# MKL28T7_CORE1 register map
Vendor: Freescale Semiconductor, Inc.; Series: Kinetis_L; File version: 1.6
CPU: CM0PLUS r0p0, little endian, no MPU, no FPU, VTOR, 2 interrupt priority bits
Registers are 32-bit, read-write, reset 0x0 unless marked. A register's access mark holds for its fields unless they carry their own. Offsets are from the block's base; [hi:lo] are bit positions; {n}, {i} and the like mark numbered series; 'fields as' and 'values as' point back to an identical list.

## XRDC
Base 0x40014000; register names take the prefix XRDC_
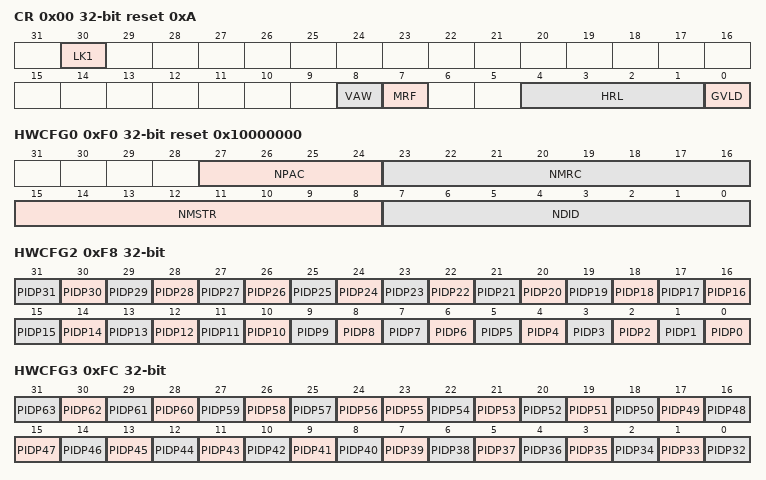
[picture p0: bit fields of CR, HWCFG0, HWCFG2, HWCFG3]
0x00 CR reset 0xA — Control Register
  [30] LK1 — 1-bit Lock
    0=Register can be written by any secure privileged write; 1=Register is locked (read-only) until the next reset
  [8] VAW ro — Virtualization aware
    0=Implementation is not virtualization aware; 1=Implementation is virtualization aware
  [7] MRF ro — Memory Region Format
    0=Kinetis format based on ARM Cortex-M processor core definition
  [4:1] HRL ro — Hardware Revision Level
  [0] GVLD — Global Valid (XRDC global enable/disable).
    0=XRDC is disabled. All accesses from all bus masters to all slaves are allowed.; 1=XRDC is enabled
0xF0 HWCFG0 ro reset 0x10000000 — Hardware Configuration Register 0
  [27:24] NPAC — Number of PACs
  [23:16] NMRC — Number of MRCs
  [15:8] NMSTR — Number of bus masters
  [7:0] NDID — Number of domains
0xF4 HWCFG1 ro — Hardware Configuration Register 1
  [3:0] DID — Domain identifier number
0xF8 HWCFG2 ro reset not defined — Hardware Configuration Register 2
  [n] PIDP{n} (n=0..31) — Process identifier present from bus master {n}
    0=Bus master {n} does not source a process identifier register. The XRDC_MDAC logic provides the needed PID for processor cores.; 1=Bus master {n} sources a process identifier register to the XRDC_MDAC logic
0xFC HWCFG3 ro reset not defined — Hardware Configuration Register 3
  [n-32] PIDP{n} (n=56..63) — Process identifier present from bus master {n}
    values as HWCFG2.PIDP0
  [23] PIDP55 — Process identifier present from bus master 55
    0=Bus master 55 does not source a process identifier register. The XRDC_MDAC logic provides the needed PID for processor cores.; 1=Bus master 55sources a process identifier register to the XRDC_MDAC logic
  [n-32] PIDP{n} (n=32..54) — Process identifier present from bus master {n}
    values as HWCFG2.PIDP0
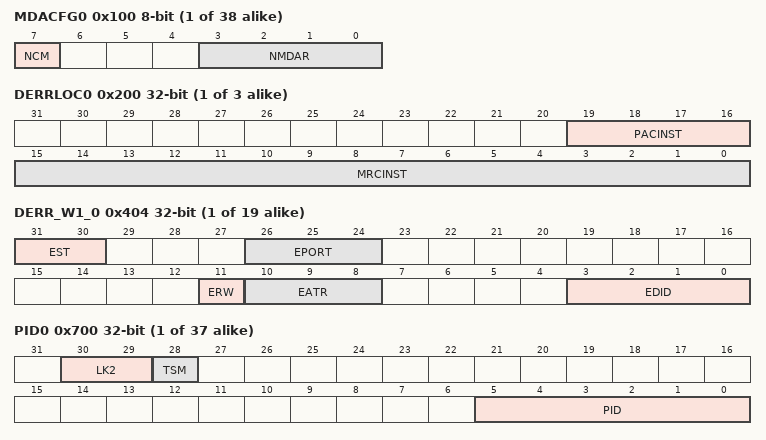
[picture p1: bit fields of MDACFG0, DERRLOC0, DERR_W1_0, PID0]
{0x100+i} MDACFG{i} (i=0..37) 8-bit ro — Master Domain Assignment Configuration Register
  [7] NCM — Non-CPU Master
    0=Bus master is a processor; 1=Bus master is a non-processor
  [3:0] NMDAR — Number of master domain assignment registers for bus master n
{0x140+i} MRCFG{i} (i=0..1) 8-bit ro — Memory Region Configuration Register
  [4:0] NMGD — Number of memory region descriptors for MRC i
{0x200+4i} DERRLOC{i} (i=0..2) ro — Domain Error Location Register
  [19:16] PACINST — PAC instance
    0=The PAC has not detected an access violation or is not physically present; 1=The PAC has detected one or more access violations for this domain
  [15:0] MRCINST — MRC instance
    0=The MRC has not detected an access violation or is not physically present; 1=The MRC has detected one or more access violations for this domain
{0x400+0x10*i} DERR_W0_{i} (i=0..18) ro — Domain Error Word0 Register
  [31:0] EADDR — Error address. This is the access address that generated an access violation.
{0x404+0x10*i} DERR_W1_{i} (i=0..18) ro — Domain Error Word1 Register
  [31:30] EST — Error state
    0=No access violation has been detected; 1=No access violation has been detected; 2=A single access violation has been detected; 3=Multiple access violations for this domain have been detected by this submodule instance. Only the address and attribute information for the first error have been captured in DERR_W0_n and DERR_W1_n.
  [26:24] EPORT — Error port
  [11] ERW — Error read/write
    0=Read access; 1=Write access
  [10:8] EATR — Error attributes. This field captures certain attributes of the access violation.
    0=Secure user mode, instruction fetch access; 1=Secure user mode, data access; 2=Secure privileged mode, instruction fetch access; 3=Secure privileged mode, data access; 4=Nonsecure user mode, instruction fetch access; 5=Nonsecure user mode, data access; 6=Nonsecure privileged mode, instruction fetch access; 7=Nonsecure privileged mode, data access
  [3:0] EDID — Error domain identifier. This field captures the domain identifier of the access violation.
{0x408+0x10*i} DERR_W2_{i} (i=0..18) ro — Domain Error Word2 Register
{0x40C+0x10*i} DERR_W3_{i} (i=0..18) — Domain Error Word3 Register
  [31:30] RECR wo — Rearm Error Capture Registers
{0x700+4i} PID{i} (i=0..36) — Process Identifier
  [30:29] LK2 — Lock
    0=Register can be written by any secure privileged write; 1=Register can be written by any secure privileged write; 2=Register can only be written by a secure privileged write from bus master n; 3=Register is locked (read-only) until the next reset
  [28] TSM — Three-state model
  [5:0] PID — Process identifier
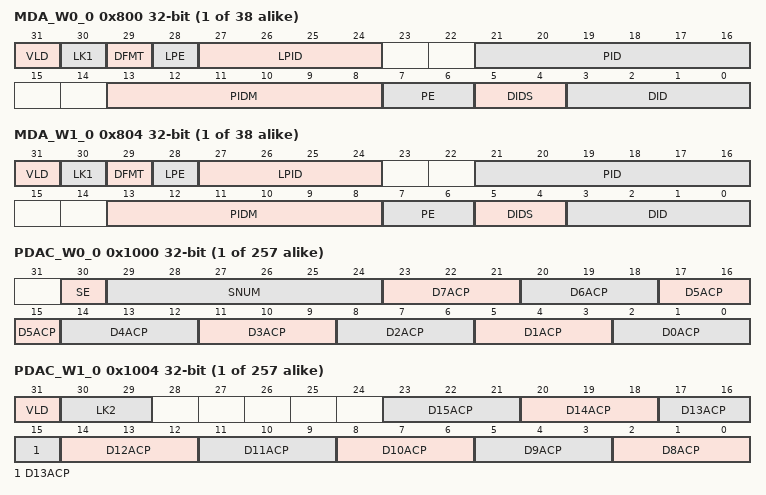
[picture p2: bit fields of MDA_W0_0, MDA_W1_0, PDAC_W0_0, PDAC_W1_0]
{0x800+0x20*i} MDA_W0_{i} (i=0..37) — Master Domain Assignment Wm,n (DFMT=0)
  [31] VLD — Valid
    0=The Wm domain assignment is invalid; 1=The Wm domain assignment is valid
  [30] LK1 — 1-bit Lock
    values as CR.LK1
  [29] DFMT ro — Domain format
  [28] LPE — Logical partition enable
  [27:24] LPID — Logical partition Identifier
  [21:16] PID — Process Identifier
  [13:8] PIDM — Process Identifier Mask
  [7:6] PE — Process identifier enable
    0=No process identifier is included in the domain hit evaluation; 1=No process identifier is included in the domain hit evaluation; 2=The process identifier is included in the domain hit evaluation as defined by the expression: partial_domain_hit = (PE == 2) && ((PID & ~PIDM) == (XRDC_PIDn[PID] & ~PIDM)); 3=The process identifier is included in the domain hit evaluation as defined by the expression: partial_domain_hit = (PE == 3) && ((PID & ~PIDM) == (XRDC_PIDn[PID] & ~PIDM))
  [5:4] DIDS — DID Select
    0=Use MDAn[3:0] as the domain identifier; 1=Use the input DID as the domain identifier; 2=Use MDAn[3:2] concatenated with the low-order 2 bits of the input DID (DID_in[1:0]) as the domain identifier
  [3:0] DID — Domain identifier
{0x804+0x20*i} MDA_W1_{i} (i=0..37) — Master Domain Assignment Wm,n (DFMT=0)
  fields as MDA_W0_0
{0x1000+8i} PDAC_W0_{i} (i=0..256) — Peripheral Domain Access Control W0
  [30] SE — Semaphore enable
    0=Do not include a semaphore in the DxACP evaluation; 1=Include the semaphore defined by W0[SNUM] in the DxACP evaluation
  [29:24] SNUM — Semaphore number. Include this hardware semaphore in the DxACP access evaluation.
  [23:21] D7ACP — Domain 7 access control policy
  [3n+2:3n] D{n}ACP (n=0..6) — Domain {n} access control policy. See description for D7ACP .
{0x1004+8i} PDAC_W1_{i} (i=0..256) — Peripheral Domain Access Control W1
  [31] VLD — Valid
    0=The PDACn assignment is invalid; 1=The PDACn assignment is valid
  [30:29] LK2 — Lock
    0=Entire PDACn can be written; 1=Entire PDACn can be written; 2=Domain "x" can only update the DxACP field; no other PDACn fields can be written; 3=PDACn is locked (read-only) until the next reset
  [3n-22:3n-24] D{n}ACP (n=8..15) — Domain {n} access control policy. See description for D7ACP .
{0x2000+0x20*i} MRGD_W0_{i} (i=0..23) — Memory Region Descriptor W0
  [31:5] BASEADDR — Base Address
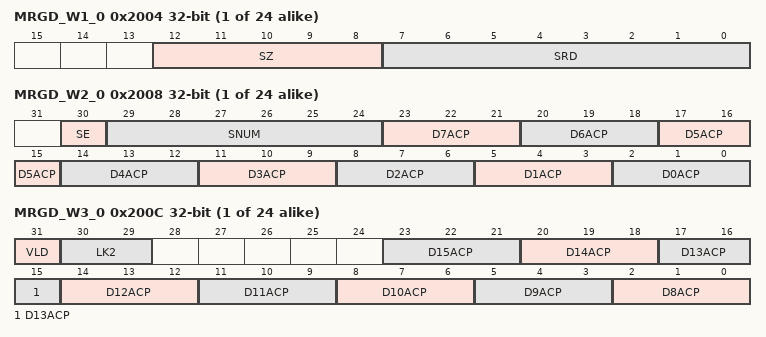
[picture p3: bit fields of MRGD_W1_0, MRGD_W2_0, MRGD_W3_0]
{0x2004+0x20*i} MRGD_W1_{i} (i=0..23) — Memory Region Descriptor W1
  [12:8] SZ — Region size
  [7:0] SRD — Subregion disable
{0x2008+0x20*i} MRGD_W2_{i} (i=0..23) — Memory Region Descriptor W2
  [30] SE — Semaphore enable
    0=Do not include a semaphore in the DxACP evaluation; 1=Include the semaphore defined by W2[SNUM] in the DxACP evaluation
  [29:24] SNUM — Semaphore number. Include this hardware semaphore in the DxACP access evaluation.
  [23:21] D7ACP — Domain 7 access control policy
  [3n+2:3n] D{n}ACP (n=0..6) — Domain {n} access control policy. See description for D7ACP .
{0x200C+0x20*i} MRGD_W3_{i} (i=0..23) — Memory Region Descriptor W3
  [31] VLD — Valid
  [30:29] LK2 — Lock
    0=Entire MRGDn can be written; 1=Entire MRGDn can be written; 2=Domain "x" can only update the DxACP field; no other MRGDn fields can be written; 3=MRGDn is locked (read-only) until the next reset
  [3n-22:3n-24] D{n}ACP (n=8..15) — Domain {n} access control policy. See description for D7ACP .
{0x2010+0x20*i} MRGD_W4_{i} (i=0..23) ro — Memory Region Descriptor W4
{0x2014+0x20*i} MRGD_W5_{i} (i=0..23) ro — Memory Region Descriptor W5
{0x2018+0x20*i} MRGD_W6_{i} (i=0..23) ro — Memory Region Descriptor W6
{0x201C+0x20*i} MRGD_W7_{i} (i=0..23) ro — Memory Region Descriptor W7

## Notices in the file
Redistribution and use in source and binary forms, with or without modification,
are permitted provided that the following conditions are met:
o Redistributions of source code must retain the above copyright notice, this list
of conditions and the following disclaimer.
o Redistributions in binary form must reproduce the above copyright notice, this
list of conditions and the following disclaimer in the documentation and/or
other materials provided with the distribution.
o Neither the name of Freescale Semiconductor, Inc. nor the names of its
contributors may be used to endorse or promote products derived from this
software without specific prior written permission.
THIS SOFTWARE IS PROVIDED BY THE COPYRIGHT HOLDERS AND CONTRIBUTORS "AS IS" AND
ANY EXPRESS OR IMPLIED WARRANTIES, INCLUDING, BUT NOT LIMITED TO, THE IMPLIED
WARRANTIES OF MERCHANTABILITY AND FITNESS FOR A PARTICULAR PURPOSE ARE
DISCLAIMED. IN NO EVENT SHALL THE COPYRIGHT HOLDER OR CONTRIBUTORS BE LIABLE FOR
ANY DIRECT, INDIRECT, INCIDENTAL, SPECIAL, EXEMPLARY, OR CONSEQUENTIAL DAMAGES
(INCLUDING, BUT NOT LIMITED TO, PROCUREMENT OF SUBSTITUTE GOODS OR SERVICES;
LOSS OF USE, DATA, OR PROFITS; OR BUSINESS INTERRUPTION) HOWEVER CAUSED AND ON
ANY THEORY OF LIABILITY, WHETHER IN CONTRACT, STRICT LIABILITY, OR TORT
(INCLUDING NEGLIGENCE OR OTHERWISE) ARISING IN ANY WAY OUT OF THE USE OF THIS
SOFTWARE, EVEN IF ADVISED OF THE POSSIBILITY OF SUCH DAMAGE.
